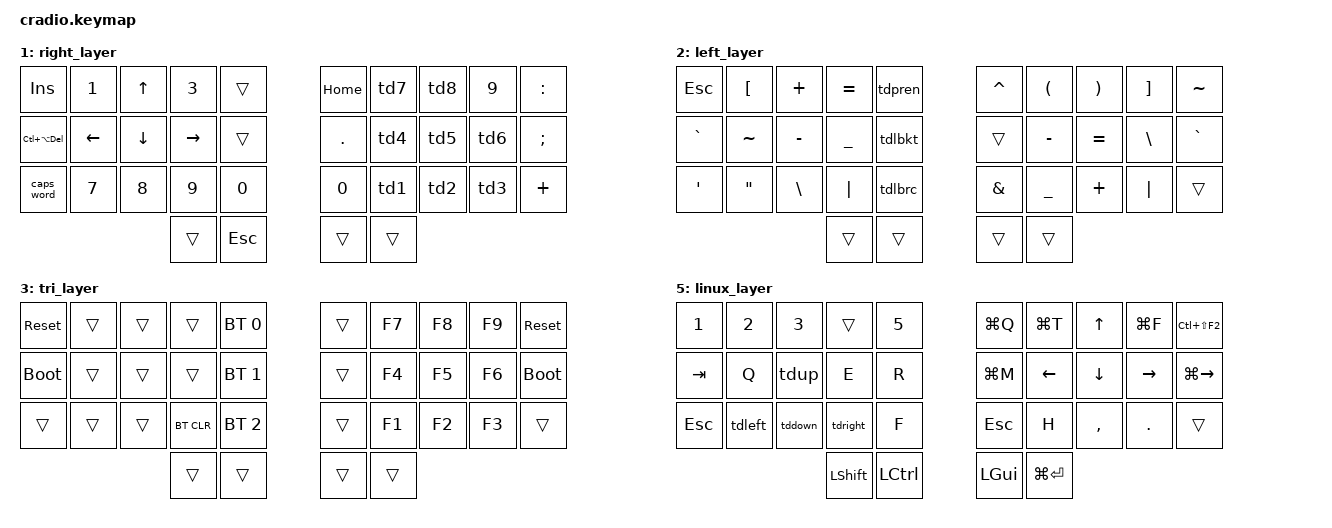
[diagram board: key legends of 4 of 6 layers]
// Copyright (c) 2022 The ZMK Contributors
// SPDX-License-Identifier: MIT

#include <behaviors.dtsi>
#include <dt-bindings/zmk/keys.h>
#include <dt-bindings/zmk/bt.h>

// Home row mods macro
#define HRML(k1,k2,k3,k4) &ht LSHFT k1  &ht LALT k2  &ht LCTRL k3  &ht LGUI k4
#define HRMR(k1,k2,k3,k4) &ht RGUI k1  &ht RCTRL k2  &ht RALT k3  &ht RSHFT k4

#define TAPPING_MS_TERM 200

#define TAPPING_GAMING_MS_TERM 270

/ {
    behaviors {
        ht: hold_tap {
            label = "hold_tap";
            compatible = "zmk,behavior-hold-tap";
            #binding-cells = <2>;
            flavor = "tap-preferred";
            tapping-term-ms = <220>;
            quick-tap-ms = <150>;
            global-quick-tap;
            bindings = <&kp>, <&kp>;
        };

        // gaming layer
            gltd1: tap_dance_gaming_1 {
                compatible = "zmk,behavior-tap-dance";
                label = "tap_dance_gaming_1";
                #binding-cells = <0>;
                tapping-term-ms = <200>;
                bindings = <&kp F>, <&kp RS(C)>;
            };

            td1F1: tap_dance_gaming_2 {
                compatible = "zmk,behavior-tap-dance";
                label = "tap_dance_gaming_2";
                #binding-cells = <0>;
                tapping-term-ms = <TAPPING_GAMING_MS_TERM>;
                bindings = <&kp N1>, <&kp F1>;
            };

            td1F2: tap_dance_gaming_3 {
                compatible = "zmk,behavior-tap-dance";
                label = "tap_dance_gaming_3";
                #binding-cells = <0>;
                tapping-term-ms = <250>;
                bindings = <&kp N2>, <&kp F2>;
            };

            td1F3: tap_dance_gaming_4 {
                compatible = "zmk,behavior-tap-dance";
                label = "tap_dance_gaming_4";
                #binding-cells = <0>;
                tapping-term-ms = <200>;
                bindings = <&kp N3>, <&kp F3>;
            };

            td1F4: tap_dance_gaming_5 {
                compatible = "zmk,behavior-tap-dance";
                label = "tap_dance_gaming_5";
                #binding-cells = <0>;
                tapping-term-ms = <200>;
                bindings = <&kp N4>, <&kp F4>;
            };

            td1F5: tap_dance_gaming_6 {
                compatible = "zmk,behavior-tap-dance";
                label = "tap_dance_gaming_6";
                #binding-cells = <0>;
                tapping-term-ms = <200>;
                bindings = <&kp N5>, <&kp F5>;
            };

            gw2ws: tap_dance_gaming_7 {
                // guildwars2 weapon swap.
                compatible = "zmk,behavior-tap-dance";
                label = "tap_dance_gaming_7";
                #binding-cells = <0>;
                tapping-term-ms = <200>;
                bindings = <&kp E>, <&kp GRAVE>;
            };

    

        // typing layer tapdance.

        td1: tap_dance_numbers_1 {
            compatible = "zmk,behavior-tap-dance";
            label = "tap_dance_numbers_1";
            #binding-cells = <0>;
            tapping-term-ms = <200>;
            bindings = <&kp N1>, <&kp RS(N1)>;
        };

        td2: tap_dance_2 {
            compatible = "zmk,behavior-tap-dance";
            label = "TAP_DANCE_2";
            #binding-cells = <0>;
			tapping-term-ms = <TAPPING_MS_TERM>;
            bindings = <&kp N2>, <&kp RS(N2)>;
        };
		td3: tap_dance_3 {
            compatible = "zmk,behavior-tap-dance";
            label = "TAP_DANCE_3";
            #binding-cells = <0>;
			tapping-term-ms = <TAPPING_MS_TERM>;
            bindings = <&kp N3>, <&kp RS(N3)>;
        };
		td4: tap_dance_4 {
            compatible = "zmk,behavior-tap-dance";
            label = "TAP_DANCE_4";
            #binding-cells = <0>;
			tapping-term-ms = <TAPPING_MS_TERM>;
            bindings = <&kp N4>, <&kp RS(N4)>;
        };
		td5: tap_dance_5 {
            compatible = "zmk,behavior-tap-dance";
            label = "TAP_DANCE_5";
            #binding-cells = <0>;
			tapping-term-ms = <TAPPING_MS_TERM>;
            bindings = <&kp N5>, <&kp RS(N5)>;
        };
		td6: tap_dance_6 {
            compatible = "zmk,behavior-tap-dance";
            label = "TAP_DANCE_6";
            #binding-cells = <0>;
			tapping-term-ms = <TAPPING_MS_TERM>;
            bindings = <&kp N6>, <&kp RS(N6)>;
        };
		td7: tap_dance_7 {
            compatible = "zmk,behavior-tap-dance";
            label = "TAP_DANCE_7";
            #binding-cells = <0>;
			tapping-term-ms = <TAPPING_MS_TERM>;
            bindings = <&kp N7>, <&kp RS(N7)>;
        };
		td8: tap_dance_8 {
            compatible = "zmk,behavior-tap-dance";
            label = "TAP_DANCE_8";
            #binding-cells = <0>;
			tapping-term-ms = <TAPPING_MS_TERM>;
            bindings = <&kp N8>, <&kp RS(N8)>;
        };
        
        tdup: tap_dance_up {
            compatible = "zmk,behavior-tap-dance";
            label = "TAP_DANCE_up";
            #binding-cells = <0>;
			tapping-term-ms = <220>;
            bindings = <&kp LS(DOWN)>, <&kt W>;
        };

        tddown: tap_dance_down {
            compatible = "zmk,behavior-tap-dance";
            label = "TAP_DANCE_down";
            #binding-cells = <0>;
			tapping-term-ms = <220>;
            bindings = <&kp S>, <&kt S>;
        };

        tdleft: tap_dance_left {
            compatible = "zmk,behavior-tap-dance";
            label = "TAP_DANCE_left";
            #binding-cells = <0>;
			tapping-term-ms = <220>;
            bindings = <&kp A>, <&kt A>;
        };

        tdright: tap_dance_right {
            compatible = "zmk,behavior-tap-dance";
            label = "TAP_DANCE_right";
            #binding-cells = <0>;
			tapping-term-ms = <220>;
            bindings = <&kp D>, <&kt D>;
        };

        // symbols td

        tdpren: tap_dance_pren {
            compatible = "zmk,behavior-tap-dance";
            label = "TAP_DANCE_pren";
            #binding-cells = <0>;
			tapping-term-ms = <TAPPING_MS_TERM>;
            bindings = <&kp LEFT_PARENTHESIS>, <&kp RIGHT_PARENTHESIS>;
        };
        tdlbkt: tap_dance_lbkt {
            compatible = "zmk,behavior-tap-dance";
            label = "TAP_DANCE_lbkt";
            #binding-cells = <0>;
			tapping-term-ms = <TAPPING_MS_TERM>;
            bindings = <&kp LEFT_BRACKET>, <&kp RIGHT_BRACKET>;
        };
        tdlbrc: tap_dance_lbrc {
            compatible = "zmk,behavior-tap-dance";
            label = "TAP_DANCE_lbrc";
            #binding-cells = <0>;
			tapping-term-ms = <TAPPING_MS_TERM>;
            bindings = <&kp LEFT_BRACE>, <&kp RIGHT_BRACE>;
        };
    };

    conditional_layers {
        compatible = "zmk,conditional-layers";
        tri_layer {
            if-layers = <1 2>;
            then-layer = <3>;
        };
    };

    combos {
        compatible = "zmk,combos";
        copy_combo {
        timeout-ms = <50>;
        key-positions = <10 13>;
        bindings = <&kp LC(C)>;
        layers = <0>;
        };

        paste_combo {
        timeout-ms = <50>;
        key-positions = <10 23>;
        bindings = <&kp LC(V)>;
        layers = <0>;
        };

        save_combo {
        timeout-ms = <50>;
        key-positions = <10 12>;
        bindings = <&kp LC(S)>;
        layers = <0>;
        };

        layer2stick_combo {
        timeout-ms = <50>;
        key-positions = <10 14>;
        bindings = <&tog 1>;
        layers = <0 1>;
        };

        layer4stick_combo {
        timeout-ms = <50>;
        key-positions = <0 9>;
        bindings = <&tog 4>;
        layers = <0 4>;
        };

        enter_combo {
        timeout-ms = <50>;
        key-positions = <11 12 13>;
        bindings = <&kp ENTER>;
        layers = <0 1>;
        };

        backspace_combo {
        timeout-ms = <50>;
        key-positions = <16 17 18>;
        bindings = <&kp BSPC>;
        layers = <0 1>;
        };

        printscreen_combo {
        timeout-ms = <50>;
        key-positions = < 23 26>;
        bindings = <&kp PRINTSCREEN>;
        layers = <0>;
        };

        capslock_combo {
        timeout-ms = <50>;
        key-positions = <3 13>;
        bindings = <&kp CAPS>;
        layers = <0>;
        };

        delete_combo {
        timeout-ms = <50>;
        key-positions = <14 24>;
        bindings = <&kp DEL>;
        layers = <0 1>;
        };

        backspace2_combo {
        timeout-ms = <50>;
        key-positions = <4 14>;
        bindings = <&kp BACKSPACE>;
        layers = <0 1>;
        };

        return_combo {
        timeout-ms = <50>;
        key-positions = <2 12>;
        bindings = <&kp ENTER>;
        layers = <0 1>;
        };

        space_combo {
        timeout-ms = <50>;
        key-positions = <6 16>;
        bindings = <&kp SPACE>;
        layers = <0 1>;
        };
        
        // gaming combos.

        gamelayer_c_combo {
        timeout-ms = <50>;
        key-positions = <2 12>;
        bindings = <&gltd1>;
        layers = <4>;
        };

        guildwar_2_combo_weaponswap {
        timeout-ms = <50>;
        key-positions = <3 13>;
        bindings = <&kp GRAVE>;
        layers = <4>;
        };

        guildwar_2_heals {
        timeout-ms = <50>;
        key-positions = <4 14>;
        bindings = <&kp N6>;
        layers = <4>; // gaming layer
        };

        guildwar_2_combo_mount {
        timeout-ms = <50>;
        key-positions = <12 22>;
        bindings = <&kp X>;
        layers = <4>;
        };

        guildwar_2_combo_7 {
        timeout-ms = <50>;
        key-positions = <1 11>;
        bindings = <&kp N7>;
        layers = <4>;
        };

        gamelayer_f5_combo {
        timeout-ms = <50>;
        key-positions = <0 10>;
        bindings = <&kp F5>;
        layers = <4>;
        };

        gamelayer_f8_combo {
        timeout-ms = <50>;
        key-positions = <10 20>;
        bindings = <&kp F8>;
        layers = <4>;
        };


        
    };

    keymap {
        compatible = "zmk,keymap";
        default_layer {
            bindings = <
        //╭──────────┬──────────┬──────────┬──────────┬──────────╮   ╭──────────┬──────────┬──────────┬──────────┬──────────╮
        //│  Q       │  W       │  E       │  R       │  T       │   │  Y       │  U       │  I       │  O       │  P       │
            &kp Q      &kp W      &kp F      &lt 5 P    &kp B          &kp J      &kp L      &kp U      &kp Y      &key_repeat
        //├──────────┼──────────┼──────────┼──────────┼──────────┤   ├──────────┼──────────┼──────────┼──────────┼──────────┤
        //│  A       │  S       │  D       │  F       │  G       │   │  H       │  J       │  K       │  L       │ ' "      │
            HRML(A,        R,         S,         T)     &lt 1 G         &lt 2 M      HRMR(N,        E,         I,        O)
        //├──────────┼──────────┼──────────┼──────────┼──────────┤   ├──────────┼──────────┼──────────┼──────────┼──────────┤
        //│  Z       │  X       │  C       │  V       │  B       │   │  N       │  M       │ , <      │ . >      │ / ?      │
            &kp Z      &kp X      &kp C      &kp D      &kp V          &kp K      &kp H      &kp COMMA  &kp DOT    &kp FSLH
        //╰──────────┴──────────┴──────────┼──────────┼──────────┤   ├──────────┼──────────┼──────────┴──────────┴──────────╯
                                            &lt 2 TAB   &kp LG(RS(UP))  &kp BSPC  &lt 1 SPACE
        //                                 ╰──────────┴──────────╯   ╰──────────┴──────────╯
            >;
        };

        right_layer {
            bindings = <    
        //╭──────────┬──────────┬──────────┬──────────┬──────────╮   ╭──────────┬──────────┬──────────┬──────────┬──────────╮
        //│ INSERT   │  1       │  2       │  3       │          │   │ HOME     │ PAGE DN  │ PAGE UP  │ END      │  :       │
            &kp INS    &kp N1     &kp UP     &kp N3     &trans         &kp HOME   &td7     &td8     &kp N9    &kp COLON
        //├──────────┼──────────┼──────────┼──────────┼──────────┤   ├──────────┼──────────┼──────────┼──────────┼──────────┤
        //│ DELETE   │  4       │  5       │  6       │          │   │ LEFT     │ DOWN     │ UP       │ RIGHT    │  ;       │
            &kp LC(LA(DEL))  &kp LEFT     &kp DOWN     &kp RIGHT     &trans         &kp DOT   &td4   &td5   &td6   &kp SEMI
        //├──────────┼──────────┼──────────┼──────────┼──────────┤   ├──────────┼──────────┼──────────┼──────────┼──────────┤
        //│ CAPS     │  7       │  8       │  9       │  0       │   │          │          │          │          │          │
           &caps_word  &kp N7     &kp N8     &kp N9     &kp N0         &kp N0     &td1    &td2     &td3    &kp PLUS
        //╰──────────┴──────────┴──────────┼──────────┼──────────┤   ├──────────┼──────────┼──────────┴──────────┴──────────╯
                                             &trans     &kp ESC        &trans     &trans
        //                                 ╰──────────┴──────────╯   ╰──────────┴──────────╯
            >;
        };

        left_layer {
            bindings = <
        //╭──────────┬──────────┬──────────┬──────────┬──────────╮   ╭──────────┬──────────┬──────────┬──────────┬──────────╮
        //│          │  [       │  {       │  }       │          │   │  ^       │  (       │  )       │  ]       │  ~       │
            &kp ESC     &kp LBKT   &kp PLUS   &kp EQUAL &tdpren         &kp CARET  &kp LPAR   &kp RPAR   &kp RBKT   &kp TILDE
        //├──────────┼──────────┼──────────┼──────────┼──────────┤   ├──────────┼──────────┼──────────┼──────────┼──────────┤
        //│  !       │  @       │  #       │  $       │  %       │   │  *       │  -       │  =       │  \       │  `       │
            &kp GRAVE &kp TILDE &kp MINUS   &kp UNDER   &tdlbkt      &trans  &kp MINUS  &kp EQUAL  &kp BSLH   &kp GRAVE
        //├──────────┼──────────┼──────────┼──────────┼──────────┤   ├──────────┼──────────┼──────────┼──────────┼──────────┤
        //│          │          │          │          │          │   │  &       │  _       │  +       │  │       │          │
            &kp APOS    &kp DQT  &kp BSLH  &kp PIPE     &tdlbrc         &kp AMPS   &kp UNDER  &kp PLUS   &kp PIPE   &trans
        //╰──────────┴──────────┴──────────┼──────────┼──────────┤   ├──────────┼──────────┼──────────┴──────────┴──────────╯
                                             &trans     &trans         &trans     &trans
        //                                 ╰──────────┴──────────╯   ╰──────────┴──────────╯
            >;
        };

        tri_layer {
            bindings = <
        //╭──────────┬──────────┬──────────┬──────────┬──────────╮   ╭──────────┬──────────┬──────────┬──────────┬──────────╮
        //│ RESET    │          │          │          │PROFILE 0 │   │          │          │          │          │  RESET   │
           &sys_reset  &trans     &trans     &trans    &bt BT_SEL 0    &trans     &kp F7     &kp F8     &kp F9    &sys_reset
        //├──────────┼──────────┼──────────┼──────────┼──────────┤   ├──────────┼──────────┼──────────┼──────────┼──────────┤
        //│BOOTLOADER│          │          │          │PROFILE 1 │   │          │          │          │          │BOOTLOADER│
          &bootloader  &trans     &trans     &trans    &bt BT_SEL 1    &trans     &kp F4     &kp F5     &kp F6    &bootloader
        //├──────────┼──────────┼──────────┼──────────┼──────────┤   ├──────────┼──────────┼──────────┼──────────┼──────────┤
        //│          │          │          │ CLEAR BT │PROFILE 2 │   │          │          │          │          │          │
            &trans     &trans     &trans    &bt BT_CLR &bt BT_SEL 2    &trans     &kp F1     &kp F2     &kp F3     &trans
        //╰──────────┴──────────┴──────────┼──────────┼──────────┤   ├──────────┼──────────┼──────────┴──────────┴──────────╯
                                             &trans     &trans         &trans     &trans
        //                                 ╰──────────┴──────────╯   ╰──────────┴──────────╯
            >;
        };

        gaming_layer {
            bindings = <
        
            &td1F1      &td1F2      &td1F3      &td1F4      &td1F5          &kp C_VOLUME_UP      &kp L      &kp I      &kp Y      &kp P
            &kp TAB     &kp N7       &kp LS(DOWN)  &kp N8       &kp N9          &kp C_VOLUME_DOWN     HRMR(N,        E,         I,        O)
            &kp ESC     &tdleft     &tddown     &tdright      &kp F          &kp M      &kp H      &kp COMMA  &kp DOT    &trans
                                            &kp LEFT_SHIFT   &kp SPACE     &kp BSPC  &lt 1 SPACE
        
            >;
        };

        linux_layer {
            bindings = <
        
            &kp N1      &kp N2      &kp N3      &trans      &kp N5          &kp LG(Q)      &kp LG(T)      &kp UP      &kp LG(F)      &kp LC(LS(F2))
            &kp TAB     &kp Q       &tdup      &kp E       &kp R          &kp LG(M)    &kp LEFT &kp DOWN &kp RIGHT &kp LG(RIGHT)
            &kp ESC     &tdleft     &tddown     &tdright      &kp F          &kp ESC      &kp H      &kp COMMA  &kp DOT    &trans
                                            &kp LEFT_SHIFT   &kp LEFT_CONTROL     &kp LEFT_GUI  &kp LG(ENTER)
        
            >;
        };
    };
};
